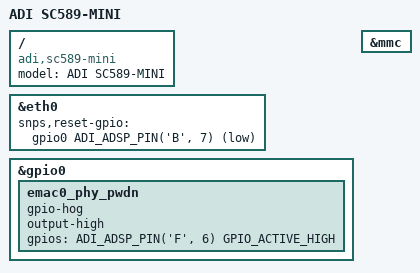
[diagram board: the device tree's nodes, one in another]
// SPDX-License-Identifier: GPL-2.0-or-later
/*
 * (C) Copyright 2024 - Analog Devices, Inc.
 */

/dts-v1/;

#include "sc58x.dtsi"

/ {
	model = "ADI SC589-MINI";
	compatible = "adi,sc589-mini", "adi,sc58x";
};

&eth0 {
	snps,reset-gpio = <&gpio0 ADI_ADSP_PIN('B', 7) GPIO_ACTIVE_LOW>;
};

&gpio0 {
	emac0_phy_pwdn {
		gpio-hog;
		output-high;
		gpios = <ADI_ADSP_PIN('F', 6) GPIO_ACTIVE_HIGH>;
	};
};

&mmc {
	status = "okay";
};
